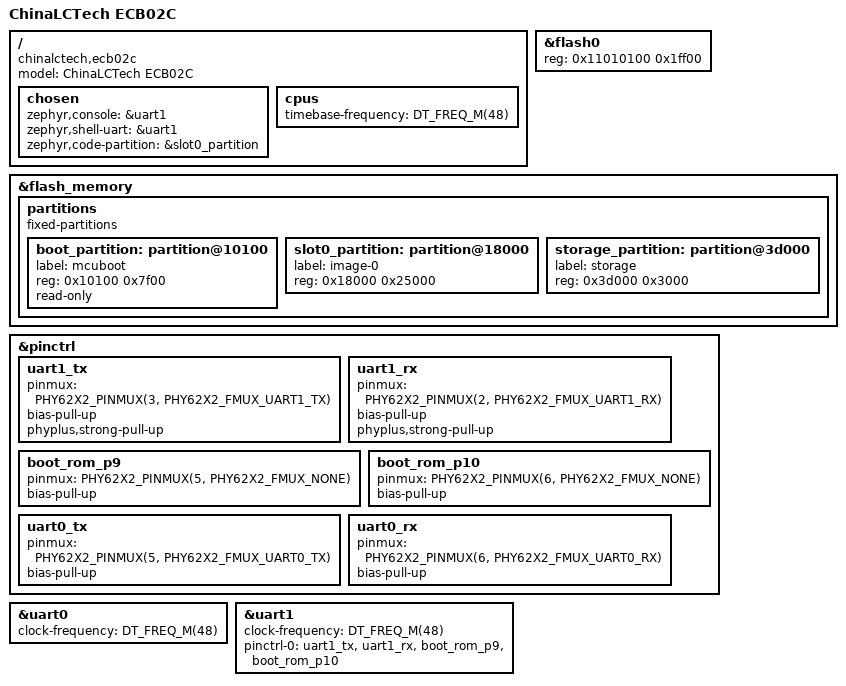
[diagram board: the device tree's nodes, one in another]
/*
 * SPDX-FileCopyrightText: Copyright The Zephyr Project Contributors
 * SPDX-License-Identifier: Apache-2.0
 */

/dts-v1/;

#include <phyplus/phy62x2.dtsi>

/ {
	model = "ChinaLCTech ECB02C";
	compatible = "chinalctech,ecb02c";

	chosen {
		zephyr,console = &uart1;
		zephyr,shell-uart = &uart1;
		zephyr,code-partition = &slot0_partition;
	};

	cpus {
		timebase-frequency = <DT_FREQ_M(48)>;
	};
};

&flash0 {
	reg = <0x11010100 0x1ff00>;
};

&flash_memory {
	partitions {
		compatible = "fixed-partitions";
		#address-cells = <1>;
		#size-cells = <1>;

		/* MCUboot at 0x10100, XIP, and the one slot of the application */
		boot_partition: partition@10100 {
			label = "mcuboot";
			reg = <0x10100 0x7f00>;
			read-only;
		};

		slot0_partition: partition@18000 {
			label = "image-0";
			reg = <0x18000 0x25000>;
		};

		storage_partition: partition@3d000 {
			label = "storage";
			reg = <0x3d000 0x3000>;
		};
	};
};

&pinctrl {
	/*
	 * UART1 on P2 and P3, the pads that the USB-UART of the module is wired to, with TX of the
	 * chip on P3 and RX on P2.
	 */
	uart1_tx: uart1_tx {
		pinmux = <PHY62X2_PINMUX(3, PHY62X2_FMUX_UART1_TX)>;
		bias-pull-up;
		phyplus,strong-pull-up;
	};

	uart1_rx: uart1_rx {
		pinmux = <PHY62X2_PINMUX(2, PHY62X2_FMUX_UART1_RX)>;
		bias-pull-up;
		phyplus,strong-pull-up;
	};

	/*
	 * P9 and P10 are the pins of the boot ROM loader, which looks for its string on P10 after every
	 * reset: when the console is on UART1 they stay GPIO with a pull-up, a floating input must not
	 * look like the string.
	 */
	boot_rom_p9: boot_rom_p9 {
		pinmux = <PHY62X2_PINMUX(5, PHY62X2_FMUX_NONE)>;
		bias-pull-up;
	};

	boot_rom_p10: boot_rom_p10 {
		pinmux = <PHY62X2_PINMUX(6, PHY62X2_FMUX_NONE)>;
		bias-pull-up;
	};

	/* UART0 on P9 (TX) and P10 (RX), for a module that is wired there, see the overlay */
	uart0_tx: uart0_tx {
		pinmux = <PHY62X2_PINMUX(5, PHY62X2_FMUX_UART0_TX)>;
		bias-pull-up;
	};

	uart0_rx: uart0_rx {
		pinmux = <PHY62X2_PINMUX(6, PHY62X2_FMUX_UART0_RX)>;
		bias-pull-up;
	};
};

/* The board uses UART1 */
&uart0 {
	clock-frequency = <DT_FREQ_M(48)>;
};

&uart1 {
	clock-frequency = <DT_FREQ_M(48)>;
	pinctrl-0 = <&uart1_tx &uart1_rx &boot_rom_p9 &boot_rom_p10>;
	pinctrl-names = "default";
	status = "okay";
};
